# csr register map
Vendor: litex
Litex SoC 2023-06-26 23:04:12
Registers are 32-bit, read-write, reset 0x0 unless marked. A register's access mark holds for its fields unless they carry their own. Offsets are from the block's base; lines under a group give offsets from that group; [hi:lo] are bit positions; {n}, {i} and the like mark numbered series; 'fields as' and 'values as' point back to an identical list; <NAME> marks a mode.

## Memory map
0x82000000 RGB_CNTRL size 0x1C
0x82000800 CTRL size 0xC
0x82001000 ETHMAC size 0x44
0x82001800 ETHPHY size 0x4
0x82002000 IDENTIFIER_MEM size 0x4
0x82002800 SDRAM size 0x1C
0x82003000 SPISDCARD size 0x1C
0x82003800 TIMER0 size 0x2C
0x82004000 UART size 0x20

## Further device data
memoryRegions:
  ROM baseAddress=0x00000000 size=0x00012000
  SRAM baseAddress=0x10000000 size=0x00002000
  MAIN_RAM baseAddress=0x40000000 size=0x00800000
  ETHMAC baseAddress=0x80000000 size=0x00002000
  CSR baseAddress=0x82000000 size=0x00010000
constants:
  CONFIG_CLOCK_FREQUENCY value=100000000
  CONFIG_CPU_RESET_ADDR value=0
  CONFIG_CPU_TYPE_FEMTORV value=None
  CONFIG_CPU_VARIANT_STANDARD value=None
  CONFIG_CPU_HUMAN_NAME value=FemtoRV-STANDARD
  CONFIG_CPU_NOP value=nop
  UART_POLLING value=None
  CONFIG_L2_SIZE value=32768
  CONFIG_CSR_DATA_WIDTH value=32
  CONFIG_CSR_ALIGNMENT value=32
  CONFIG_BUS_STANDARD value=WISHBONE
  CONFIG_BUS_DATA_WIDTH value=32
  CONFIG_BUS_ADDRESS_WIDTH value=32
  CONFIG_BUS_BURSTING value=0
  ETHMAC_RX_SLOTS value=2
  ETHMAC_TX_SLOTS value=2
  ETHMAC_SLOT_SIZE value=2048

## RGB_CNTRL
Base 0x82000000
0x00 ADDR_A
  [11:0] addr_a
0x04 RGB_INDAT_A
  [11:0] rgb_indat_a
0x08 WR_EN
  [0] wr_en
0x0C RD_EN
  [0] rd_en
0x10 EV_STATUS — This register contains the current raw level of the ok event trigger. Writes to this register have no effect.
  [0] ok — Level of the ``ok`` event
0x14 EV_PENDING — When a ok event occurs, the corresponding bit will be set in this register. To clear the Event, set the corresponding bit in this register.
  [0] ok — `1` if a `ok` event occurred. This Event is triggered on a **falling** edge.
0x18 EV_ENABLE — This register enables the corresponding ok events. Write a ``0`` to this register to disable individual events.
  [0] ok — Write a ``1`` to enable the ``ok`` Event

## CTRL
Base 0x82000800
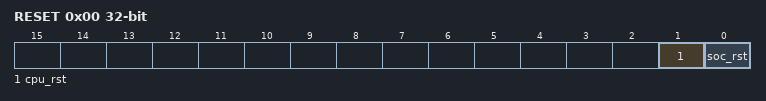
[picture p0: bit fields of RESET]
0x00 RESET
  [1] cpu_rst — Write `1` to this register to reset the CPU(s) of the SoC (Hold Reset)
  [0] soc_rst — Write `1` to this register to reset the full SoC (Pulse Reset)
0x04 SCRATCH reset 0x12345678 — Use this register as a scratch space to verify that software read/write accesses to the Wishbone/CSR bus are working correctly. The initial reset value of 0x1234578 can be used to verify endianness.
0x08 BUS_ERRORS — Total number of Wishbone bus errors (timeouts) since start.

## ETHMAC
Base 0x82001000
0x00 SRAM_WRITER_SLOT
  [0] sram_writer_slot
0x04 SRAM_WRITER_LENGTH
  [10:0] sram_writer_length
0x08 SRAM_WRITER_ERRORS
0x0C SRAM_WRITER_EV_STATUS — This register contains the current raw level of the available event trigger. Writes to this register have no effect.
  [0] available — Level of the ``available`` event
0x10 SRAM_WRITER_EV_PENDING — When a available event occurs, the corresponding bit will be set in this register. To clear the Event, set the corresponding bit in this register.
  [0] available — `1` if a `available` event occurred. This Event is **level triggered** when the signal is **high**.
0x14 SRAM_WRITER_EV_ENABLE — This register enables the corresponding available events. Write a ``0`` to this register to disable individual events.
  [0] available — Write a ``1`` to enable the ``available`` Event
0x18 SRAM_READER_START
  [0] sram_reader_start
0x1C SRAM_READER_READY
  [0] sram_reader_ready
0x20 SRAM_READER_LEVEL
  [1:0] sram_reader_level
0x24 SRAM_READER_SLOT
  [0] sram_reader_slot
0x28 SRAM_READER_LENGTH
  [10:0] sram_reader_length
0x2C SRAM_READER_EV_STATUS — This register contains the current raw level of the event0 event trigger. Writes to this register have no effect.
  [0] event0 — Level of the ``event0`` event
0x30 SRAM_READER_EV_PENDING — When a event0 event occurs, the corresponding bit will be set in this register. To clear the Event, set the corresponding bit in this register.
  [0] event0 — `1` if a this particular event occurred. This Event is triggered on a **rising** edge.
0x34 SRAM_READER_EV_ENABLE — This register enables the corresponding event0 events. Write a ``0`` to this register to disable individual events.
  [0] event0 — Write a ``1`` to enable the ``event0`` Event
0x38 PREAMBLE_CRC reset 0x1
  [0] preamble_crc
0x3C RX_DATAPATH_PREAMBLE_ERRORS
0x40 RX_DATAPATH_CRC_ERRORS
